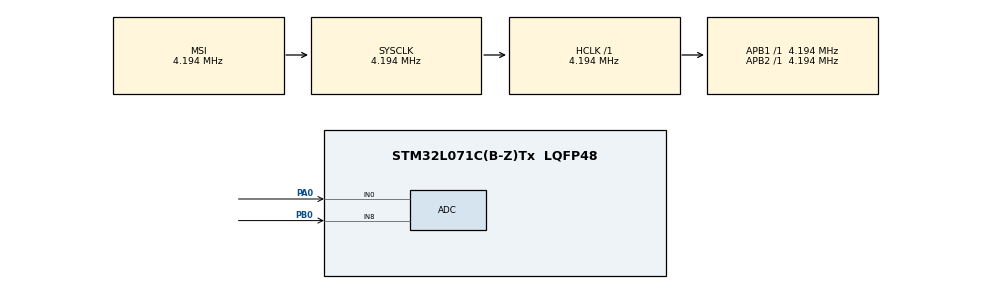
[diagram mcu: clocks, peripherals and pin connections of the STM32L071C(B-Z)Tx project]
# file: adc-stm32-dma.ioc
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ADC.ClockPrescaler=ADC_CLOCK_SYNC_PCLK_DIV1
ADC.ContinuousConvMode=ENABLE
ADC.DMAContinuousRequests=ENABLE
ADC.ExternalTrigConv=ADC_SOFTWARE_START
ADC.LowPowerAutoPowerOff=ENABLE
ADC.Overrun=ADC_OVR_DATA_OVERWRITTEN
ADC.SamplingTime=ADC_SAMPLETIME_160CYCLES_5
Dma.ADC.0.Direction=DMA_PERIPH_TO_MEMORY
Dma.ADC.0.Instance=DMA1_Channel1
Dma.ADC.0.MemDataAlignment=DMA_MDATAALIGN_HALFWORD
Dma.ADC.0.MemInc=DMA_MINC_ENABLE
Dma.ADC.0.Mode=DMA_CIRCULAR
Dma.ADC.0.PeriphDataAlignment=DMA_PDATAALIGN_HALFWORD
Dma.ADC.0.PeriphInc=DMA_PINC_DISABLE
Dma.ADC.0.Priority=DMA_PRIORITY_LOW
Dma.Request0=ADC
Mcu.Family=STM32L0
Mcu.Name=STM32L071C(B-Z)Tx
Mcu.Package=LQFP48
NVIC.ADC1_COMP_IRQn=true\:0\:0\:false\:false\:true\:true\:true\:true
NVIC.DMA1_Channel1_IRQn=true\:0\:0\:false\:false\:true\:false\:true\:true
PA0.Mode=IN0
PA0.Signal=ADC_IN0
PB0.Mode=IN8
PB0.Signal=ADC_IN8
ProjectManager.HeapSize=0x200
ProjectManager.StackSize=0x400
ProjectManager.TargetToolchain=STM32CubeIDE
RCC.AHBFreq_Value=4194000
RCC.APB1Freq_Value=4194000
RCC.APB1TimFreq_Value=4194000
RCC.APB2Freq_Value=4194000
RCC.APB2TimFreq_Value=4194000
RCC.HCLKFreq_Value=4194000
RCC.HSE_VALUE=8000000
RCC.HSI16_VALUE=16000000
RCC.HSI_VALUE=16000000
RCC.LSE_VALUE=32768
RCC.MSIClockRange=RCC_MSIRANGE_6
RCC.MSI_VALUE=4194000
RCC.SYSCLKFreq_VALUE=4194000
RCC.VCOOutputFreq_Value=48000000
board=custom

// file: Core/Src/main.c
/* USER CODE BEGIN Header */
/**
  ******************************************************************************
  * @file           : main.c
  * @brief          : Main program body
  ******************************************************************************
  * @attention
  *
  * Copyright (c) 2023 STMicroelectronics.
  * All rights reserved.
  *
  * This software is licensed under terms that can be found in the LICENSE file
  * in the root directory of this software component.
  * If no LICENSE file comes with this software, it is provided AS-IS.
  *
  ******************************************************************************
  */
/* USER CODE END Header */
#include "main.h"
#include "adc.h"
#include "dma.h"
#include "gpio.h"

/* USER CODE BEGIN PV */
uint16_t adc_value[16] = {0};
uint32_t avg_adc_value = 0;
float j1772_value = 0;
/* USER CODE END PV */

void SystemClock_Config(void);

int main(void)
{

  /* MCU Configuration--------------------------------------------------------*/

  /* Reset of all peripherals, Initializes the Flash interface and the Systick. */
  HAL_Init();

  /* Configure the system clock */
  SystemClock_Config();

  /* Initialize all configured peripherals */
  MX_GPIO_Init();
  MX_DMA_Init();
  MX_ADC_Init();
  /* USER CODE BEGIN 2 */
  HAL_ADC_Start_DMA(&hadc,(uint32_t*)adc_value ,16);
  HAL_Delay(5);
  /* USER CODE END 2 */

  /* Infinite loop */
  /* USER CODE BEGIN WHILE */
  while (1)
  {
	  avg_adc_value = 0;
	  for(uint8_t i=0;i<16;i++)
	  {
		  avg_adc_value += adc_value[i];
	  }
	  avg_adc_value = avg_adc_value / 16;
	  j1772_value = (((avg_adc_value *3.3)/ 4096));
	  j1772_value = (7.350*j1772_value) - 10.90;
	  __asm("nop");
    /* USER CODE END WHILE */

  }
}

void SystemClock_Config(void)
{
  RCC_OscInitTypeDef RCC_OscInitStruct = {0};
  RCC_ClkInitTypeDef RCC_ClkInitStruct = {0};

  /** Configure the main internal regulator output voltage
  */
  __HAL_PWR_VOLTAGESCALING_CONFIG(PWR_REGULATOR_VOLTAGE_SCALE1);

  /** Initializes the RCC Oscillators according to the specified parameters
  * in the RCC_OscInitTypeDef structure.
  */
  RCC_OscInitStruct.OscillatorType = RCC_OSCILLATORTYPE_MSI;
  RCC_OscInitStruct.MSIState = RCC_MSI_ON;
  RCC_OscInitStruct.MSICalibrationValue = 0;
  RCC_OscInitStruct.MSIClockRange = RCC_MSIRANGE_6;
  RCC_OscInitStruct.PLL.PLLState = RCC_PLL_NONE;
  if (HAL_RCC_OscConfig(&RCC_OscInitStruct) != HAL_OK)
  {
    Error_Handler();
  }

  /** Initializes the CPU, AHB and APB buses clocks
  */
  RCC_ClkInitStruct.ClockType = RCC_CLOCKTYPE_HCLK|RCC_CLOCKTYPE_SYSCLK
                              |RCC_CLOCKTYPE_PCLK1|RCC_CLOCKTYPE_PCLK2;
  RCC_ClkInitStruct.SYSCLKSource = RCC_SYSCLKSOURCE_MSI;
  RCC_ClkInitStruct.AHBCLKDivider = RCC_SYSCLK_DIV1;
  RCC_ClkInitStruct.APB1CLKDivider = RCC_HCLK_DIV1;
  RCC_ClkInitStruct.APB2CLKDivider = RCC_HCLK_DIV1;

  if (HAL_RCC_ClockConfig(&RCC_ClkInitStruct, FLASH_LATENCY_0) != HAL_OK)
  {
    Error_Handler();
  }
}

void Error_Handler(void)
{
  __disable_irq();
  while (1)
  {
  }
}
